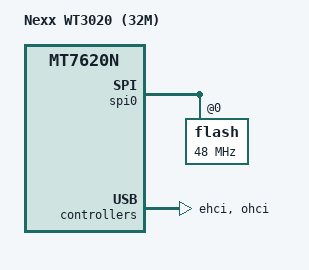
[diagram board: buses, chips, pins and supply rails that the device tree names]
#include "mt7620n_nexx_wt3020.dtsi"

/ {
	compatible = "nexx,wt3020-32m", "nexx,wt3020", "ralink,mt7620n-soc";
	model = "Nexx WT3020 (32M)";
};

&firmware {
	reg = <0x50000 0x1ec0000>;
};

&spi0 {
	flash@0 {
		spi-max-frequency = <48000000>;
	};
};

&ehci {
	status = "okay";
};

&ohci {
	status = "okay";
};
